# J7AEN_main_dbg_cbass0_ERR register map
Vendor: Texas Instruments
Peripheral module from a debugger description file (folder J722S).
Registers are 32-bit, read-only, reset 0x0 unless marked. A register's access mark holds for its fields unless they carry their own. Offsets are as the file gives them; lines under a group give offsets from that group; [hi:lo] are bit positions; {n}, {i} and the like mark numbered series; 'fields as' and 'values as' point back to an identical list; <NAME> marks a mode.

## J7AEN_main_dbg_cbass0_ERR
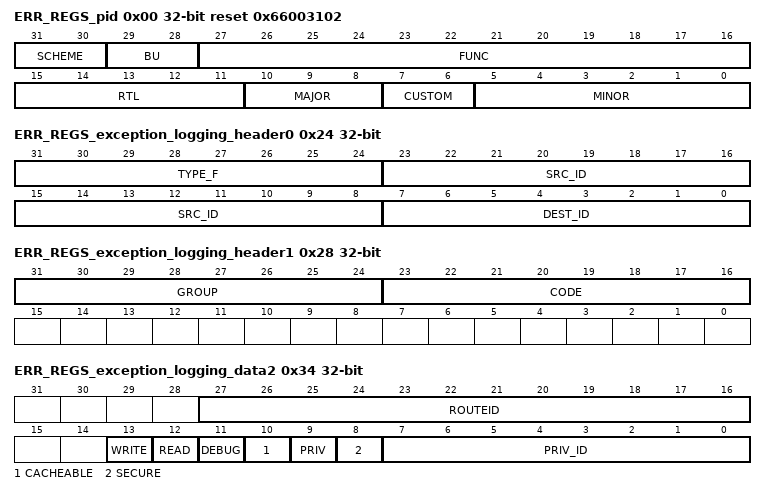
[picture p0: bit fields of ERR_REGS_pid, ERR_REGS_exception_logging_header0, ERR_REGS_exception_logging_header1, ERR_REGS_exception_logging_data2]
0x00 ERR_REGS_pid reset 0x66003102 — The Revision Register contains the major and minor revisions for the module.
  [31:30] SCHEME — PID register scheme
  [29:28] BU — Business Unit: 10 = Processors
  [27:16] FUNC — Module ID
  [15:11] RTL — RTL revision. Will vary depending on release.
  [10:8] MAJOR — Major revision
  [7:6] CUSTOM
  [5:0] MINOR — Minor revision
0x04 ERR_REGS_destination_id rw — The Destination ID Register defines the destination ID value for error messages.
  [7:0] DEST_ID — The destination ID.
0x24 ERR_REGS_exception_logging_header0 — The Exception Logging Header 0 Register contains the first word of the header.
  [31:24] TYPE_F — Type. 7 = CBASS.
  [23:8] SRC_ID — Source ID. Always 0.
  [7:0] DEST_ID — Destination ID.
0x28 ERR_REGS_exception_logging_header1 — The Exception Logging Header 1 Register contains the second word of the header.
  [31:24] GROUP — Group. Always 0.
  [23:16] CODE — Code. 0 = CBASS decode error.
0x2C ERR_REGS_exception_logging_data0 — The Exception Logging Data 0 Register contains the first word of the data.
  [31:0] ADDR_L — Address lower 32 bits.
0x30 ERR_REGS_exception_logging_data1 — The Exception Logging Data 1 Register contains the second word of the data.
  [15:0] ADDR_H — Address upper 16 bits.
0x34 ERR_REGS_exception_logging_data2 — The Exception Logging Data 2 Register contains the third word of the data.
  [27:16] ROUTEID, [13] WRITE, [12] READ, [11] DEBUG, [10] CACHEABLE, [9] PRIV, [8] SECURE, [7:0] PRIV_ID
0x38 ERR_REGS_exception_logging_data3 — The Exception Logging Data 3 Register contains the fourth word of the data.
  [9:0] BYTECNT — Byte count.
0x50 ERR_REGS_err_intr_raw_stat access not given — The interrupt raw status register indicates if there is null interrupt regardless of interrupt enable
  [0] INTR — Level Interrupt status (access R/W1TS)
0x54 ERR_REGS_err_intr_enabled_stat access not given — The interrupt status register is gated by the interrupt enable
  [0] ENABLED_INTR — Level Enabled Interrupt status (access R/W1TC)
0x58 ERR_REGS_err_intr_enable_set access not given — Only when this register is set, null access will cause interrupt to be generated.
  [0] INTR_ENABLE_SET — Interrupt Enable Set Register (access R/W1TS)
0x5C ERR_REGS_err_intr_enable_clr access not given — Setting this register disables the null interrupt generation
  [0] INTR_ENABLE_CLR — Interrupt Enable Clear Register (access R/W1TC)
0x60 ERR_REGS_err_eoi rw — Writing to EOI Register indicates that current interrupt has been serviced which then allows next interrupt to be generated
  [15:0] EOI_WR — End Of Interrupt Register
